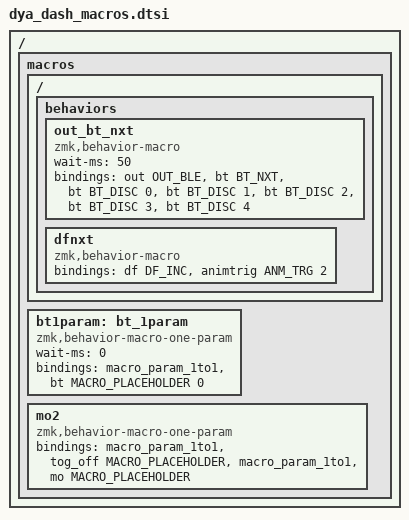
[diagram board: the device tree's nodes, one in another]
#include <behaviors.dtsi>
#include <behaviors/animation_control.dtsi>
#include <behaviors/animation_trigger.dtsi>
#include <dt-bindings/zmk/keys.h>
#include <dt-bindings/zmk/bt.h>
#include <dt-bindings/zmk/outputs.h>
#include <dt-bindings/zmk_driver_animation/animation_control.h>
#include <dt-bindings/zmk_driver_animation/animation_trigger.h>

/ {
    macros {
        ZMK_MACRO(out_bt_nxt,
            wait-ms = <50>;
            // Disconnect from all once for reliable connection to selected profile.
            // ZMK automatically reconnects to current profile right after disconnection.
            bindings = <&out OUT_BLE>, <&bt BT_NXT>, <&bt BT_DISC 0>, <&bt BT_DISC 1>, <&bt BT_DISC 2>, <&bt BT_DISC 3>, <&bt BT_DISC 4>;
        )
        ZMK_MACRO(dfnxt,
            bindings = <&df DF_INC>, <&animtrig ANM_TRG 2>;
        )
        // macro to use &bt in hold-tap. two param command is not supported in hold-tap for now.
        bt1param: bt_1param {
            compatible = "zmk,behavior-macro-one-param";
            #binding-cells = <1>;
            wait-ms = <0>;
            bindings = <&macro_param_1to1>, <&bt MACRO_PLACEHOLDER 0>;
        };
        // diactivate speficied layer and execute &mo to disable trackball temp layer disable callback
        mo2: mo2 {
            compatible = "zmk,behavior-macro-one-param";
            #binding-cells = <1>;
            bindings = <&macro_param_1to1>, <&tog_off MACRO_PLACEHOLDER>,
                       <&macro_param_1to1>, <&mo MACRO_PLACEHOLDER>;
        };
    };
};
